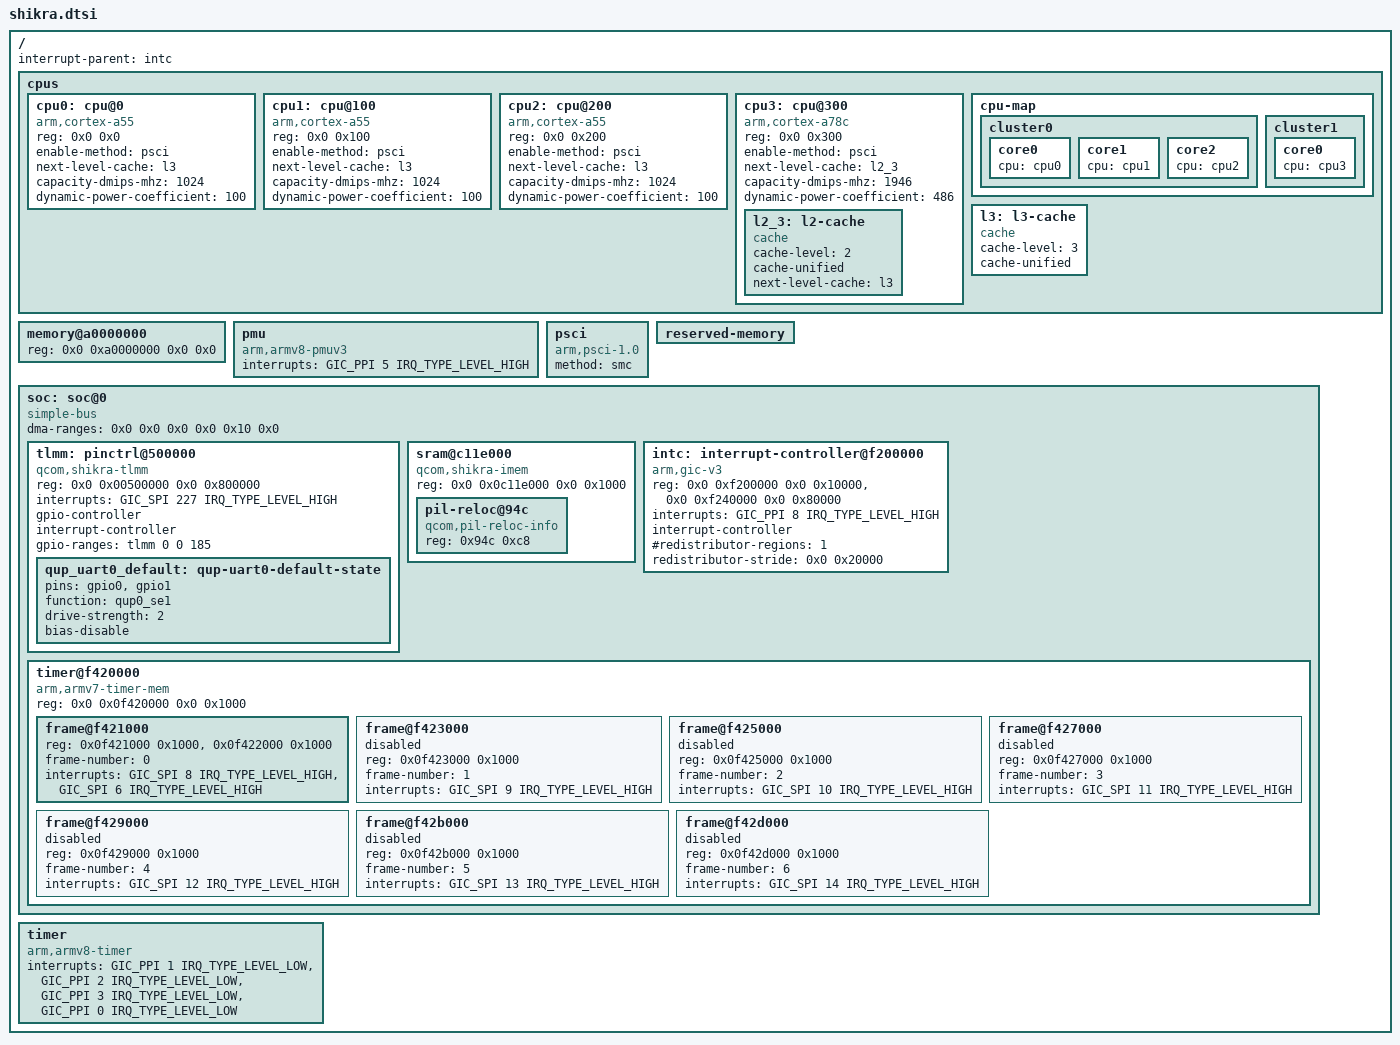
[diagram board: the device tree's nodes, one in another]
// SPDX-License-Identifier: BSD-3-Clause
/*
 * Copyright (c) Qualcomm Technologies, Inc. and/or its subsidiaries.
 */

#include <dt-bindings/interrupt-controller/arm-gic.h>

/ {
	interrupt-parent = <&intc>;

	#address-cells = <2>;
	#size-cells = <2>;

	cpus {
		#address-cells = <2>;
		#size-cells = <0>;

		cpu0: cpu@0 {
			device_type = "cpu";
			compatible = "arm,cortex-a55";
			reg = <0x0 0x0>;
			enable-method = "psci";
			next-level-cache = <&l3>;
			capacity-dmips-mhz = <1024>;
			dynamic-power-coefficient = <100>;
		};

		cpu1: cpu@100 {
			device_type = "cpu";
			compatible = "arm,cortex-a55";
			reg = <0x0 0x100>;
			enable-method = "psci";
			next-level-cache = <&l3>;
			capacity-dmips-mhz = <1024>;
			dynamic-power-coefficient = <100>;
		};

		cpu2: cpu@200 {
			device_type = "cpu";
			compatible = "arm,cortex-a55";
			reg = <0x0 0x200>;
			enable-method = "psci";
			next-level-cache = <&l3>;
			capacity-dmips-mhz = <1024>;
			dynamic-power-coefficient = <100>;
		};

		cpu3: cpu@300 {
			device_type = "cpu";
			compatible = "arm,cortex-a78c";
			reg = <0x0 0x300>;
			enable-method = "psci";
			next-level-cache = <&l2_3>;
			capacity-dmips-mhz = <1946>;
			dynamic-power-coefficient = <486>;

			l2_3: l2-cache {
				compatible = "cache";
				cache-level = <2>;
				cache-unified;
				next-level-cache = <&l3>;
			};
		};

		cpu-map {
			cluster0 {
				core0 {
					cpu = <&cpu0>;
				};

				core1 {
					cpu = <&cpu1>;
				};

				core2 {
					cpu = <&cpu2>;
				};
			};

			cluster1 {
				core0 {
					cpu = <&cpu3>;
				};
			};
		};

		l3: l3-cache {
			compatible = "cache";
			cache-level = <3>;
			cache-unified;
		};
	};

	memory@a0000000 {
		device_type = "memory";
		/* We expect the bootloader to fill in the size */
		reg = <0x0 0xa0000000 0x0 0x0>;
	};

	pmu {
		compatible = "arm,armv8-pmuv3";
		interrupts = <GIC_PPI 5 IRQ_TYPE_LEVEL_HIGH>;
	};

	psci {
		compatible = "arm,psci-1.0";
		method = "smc";
	};

	reserved-memory {
		#address-cells = <2>;
		#size-cells = <2>;
	};

	soc: soc@0 {
		compatible = "simple-bus";

		#address-cells = <2>;
		#size-cells = <2>;
		dma-ranges = <0x0 0x0 0x0 0x0 0x10 0x0>;
		ranges = <0x0 0x0 0x0 0x0 0x10 0x0>;

		tlmm: pinctrl@500000 {
			compatible = "qcom,shikra-tlmm";
			reg = <0x0 0x00500000 0x0 0x800000>;

			interrupts = <GIC_SPI 227 IRQ_TYPE_LEVEL_HIGH>;

			gpio-controller;
			#gpio-cells = <2>;

			interrupt-controller;
			#interrupt-cells = <2>;

			gpio-ranges = <&tlmm 0 0 185>;

			qup_uart0_default: qup-uart0-default-state {
				pins = "gpio0", "gpio1";
				function = "qup0_se1";
				drive-strength = <2>;
				bias-disable;
			};
		};

		sram@c11e000 {
			compatible = "qcom,shikra-imem", "syscon", "simple-mfd";
			reg = <0x0 0x0c11e000 0x0 0x1000>;
			ranges = <0x0 0x0 0x0c11e000 0x1000>;

			#address-cells = <1>;
			#size-cells = <1>;

			pil-reloc@94c {
				compatible = "qcom,pil-reloc-info";
				reg = <0x94c 0xc8>;
			};
		};

		intc: interrupt-controller@f200000 {
			compatible = "arm,gic-v3";
			reg = <0x0 0xf200000 0x0 0x10000>, /* GICD */
			      <0x0 0xf240000 0x0 0x80000>; /* GICR * 4 regions */

			interrupts = <GIC_PPI 8 IRQ_TYPE_LEVEL_HIGH>;

			#interrupt-cells = <3>;
			interrupt-controller;

			#redistributor-regions = <1>;
			redistributor-stride = <0x0 0x20000>;

			#address-cells = <2>;
			#size-cells = <2>;
			ranges;
		};

		timer@f420000 {
			compatible = "arm,armv7-timer-mem";
			reg = <0x0 0x0f420000  0x0 0x1000>;

			#address-cells = <1>;
			#size-cells = <1>;
			ranges = <0x0 0x0 0x0 0x10000000>;

			frame@f421000 {
				reg = <0x0f421000 0x1000>,
				      <0x0f422000 0x1000>;
				frame-number = <0>;
				interrupts = <GIC_SPI 8 IRQ_TYPE_LEVEL_HIGH>,
					     <GIC_SPI 6 IRQ_TYPE_LEVEL_HIGH>;
			};

			frame@f423000 {
				reg = <0x0f423000 0x1000>;
				frame-number = <1>;
				interrupts = <GIC_SPI 9 IRQ_TYPE_LEVEL_HIGH>;
				status = "disabled";
			};

			frame@f425000 {
				reg = <0x0f425000 0x1000>;
				frame-number = <2>;
				interrupts = <GIC_SPI 10 IRQ_TYPE_LEVEL_HIGH>;
				status = "disabled";
			};

			frame@f427000 {
				reg = <0x0f427000 0x1000>;
				frame-number = <3>;
				interrupts = <GIC_SPI 11 IRQ_TYPE_LEVEL_HIGH>;
				status = "disabled";
			};

			frame@f429000 {
				reg = <0x0f429000 0x1000>;
				frame-number = <4>;
				interrupts = <GIC_SPI 12 IRQ_TYPE_LEVEL_HIGH>;
				status = "disabled";
			};

			frame@f42b000 {
				reg = <0x0f42b000 0x1000>;
				frame-number = <5>;
				interrupts = <GIC_SPI 13 IRQ_TYPE_LEVEL_HIGH>;
				status = "disabled";
			};

			frame@f42d000 {
				reg = <0x0f42d000 0x1000>;
				frame-number = <6>;
				interrupts = <GIC_SPI 14 IRQ_TYPE_LEVEL_HIGH>;
				status = "disabled";
			};
		};
	};

	timer {
		compatible = "arm,armv8-timer";

		interrupts = <GIC_PPI 1 IRQ_TYPE_LEVEL_LOW>,
			     <GIC_PPI 2 IRQ_TYPE_LEVEL_LOW>,
			     <GIC_PPI 3 IRQ_TYPE_LEVEL_LOW>,
			     <GIC_PPI 0 IRQ_TYPE_LEVEL_LOW>;
	};
};
